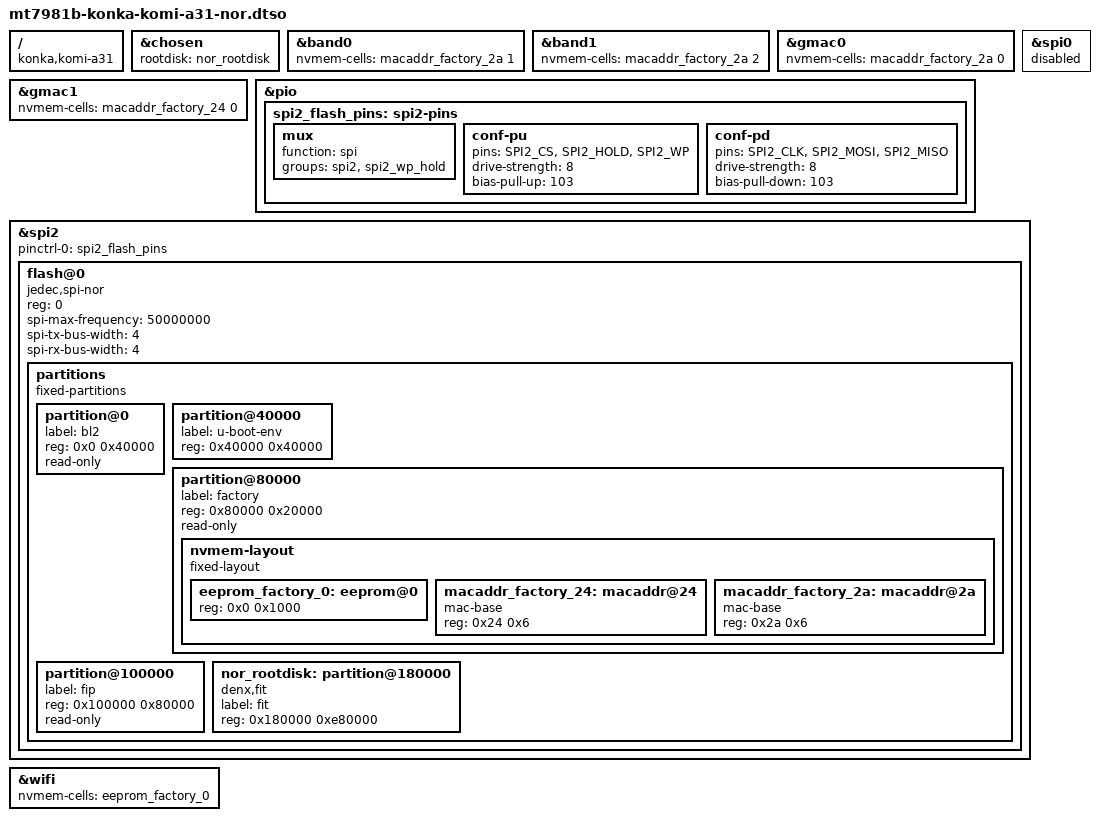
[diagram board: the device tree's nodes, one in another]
// SPDX-License-Identifier: GPL-2.0-or-later OR MIT

/dts-v1/;
/plugin/;

/ {
	compatible = "konka,komi-a31", "mediatek,mt7981";

	fragment@0 {
		target = <&chosen>;
		__overlay__ {
			rootdisk = <&nor_rootdisk>;
		};
	};

	fragment@1 {
		target = <&band0>;
		__overlay__ {
			nvmem-cells = <&macaddr_factory_2a 1>;
		};
	};

	fragment@2 {
		target = <&band1>;
		__overlay__ {
			nvmem-cells = <&macaddr_factory_2a 2>;
		};
	};

	fragment@3 {
		target = <&gmac0>;
		__overlay__ {
			nvmem-cells = <&macaddr_factory_2a 0>;
		};
	};

	fragment@4 {
		target = <&gmac1>;
		__overlay__ {
			nvmem-cells = <&macaddr_factory_24 0>;
		};
	};

	fragment@5 {
		target = <&pio>;
		__overlay__ {
			spi2_flash_pins: spi2-pins {
				mux {
					function = "spi";
					groups = "spi2", "spi2_wp_hold";
				};

				conf-pu {
					pins = "SPI2_CS", "SPI2_HOLD", "SPI2_WP";
					drive-strength = <8>;
					bias-pull-up = <103>;
				};

				conf-pd {
					pins = "SPI2_CLK", "SPI2_MOSI", "SPI2_MISO";
					drive-strength = <8>;
					bias-pull-down = <103>;
				};
			};
		};
	};

	fragment@6 {
		target = <&spi0>;
		__overlay__ {
			status = "disabled";
		};
	};

	fragment@7 {
		target = <&spi2>;
		__overlay__ {
			#address-cells = <1>;
			#size-cells = <0>;
			pinctrl-names = "default";
			pinctrl-0 = <&spi2_flash_pins>;
			status = "okay";

			flash@0 {
				compatible = "jedec,spi-nor";
				#address-cells = <1>;
				#size-cells = <1>;
				reg = <0>;

				spi-max-frequency = <50000000>;
				spi-tx-bus-width = <4>;
				spi-rx-bus-width = <4>;

				partitions {
					compatible = "fixed-partitions";
					#address-cells = <1>;
					#size-cells = <1>;

					partition@0 {
						label = "bl2";
						reg = <0x0 0x40000>;
						read-only;
					};

					partition@40000 {
						label = "u-boot-env";
						reg = <0x40000 0x40000>;
					};

					partition@80000 {
						label = "factory";
						reg = <0x80000 0x20000>;
						read-only;

						nvmem-layout {
							compatible = "fixed-layout";
							#address-cells = <1>;
							#size-cells = <1>;

							eeprom_factory_0: eeprom@0 {
								reg = <0x0 0x1000>;
							};

							macaddr_factory_24: macaddr@24 {
								compatible = "mac-base";
								reg = <0x24 0x6>;
								#nvmem-cell-cells = <1>;
							};

							macaddr_factory_2a: macaddr@2a {
								compatible = "mac-base";
								reg = <0x2a 0x6>;
								#nvmem-cell-cells = <1>;
							};
						};
					};

					partition@100000 {
						label = "fip";
						reg = <0x100000 0x80000>;
						read-only;
					};

					nor_rootdisk: partition@180000 {
						compatible = "denx,fit";
						label = "fit";
						reg = <0x180000 0xe80000>;
					};
				};
			};
		};
	};

	fragment@8 {
		target = <&wifi>;
		__overlay__ {
			nvmem-cells = <&eeprom_factory_0>;
		};
	};
};
